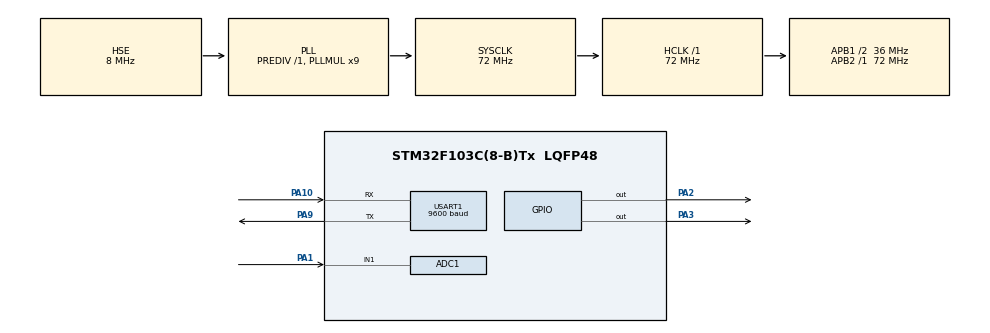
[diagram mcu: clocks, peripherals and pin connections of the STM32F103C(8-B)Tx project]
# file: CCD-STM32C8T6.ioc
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ADC1.Channel-0\#ChannelRegularConversion=ADC_CHANNEL_1
ADC1.NbrOfConversionFlag=1
ADC1.Rank-0\#ChannelRegularConversion=1
ADC1.SamplingTime-0\#ChannelRegularConversion=ADC_SAMPLETIME_1CYCLE_5
ADC1.master=1
Mcu.Family=STM32F1
Mcu.Name=STM32F103C(8-B)Tx
Mcu.Package=LQFP48
NVIC.PriorityGroup=NVIC_PRIORITYGROUP_4
NVIC.TIM2_IRQn=true\:0\:0\:false\:false\:true\:true\:true
NVIC.USART1_IRQn=true\:0\:0\:false\:false\:true\:true\:true
PA1.Signal=ADCx_IN1
PA10.Mode=Asynchronous
PA10.Signal=USART1_RX
PA13.Mode=Serial_Wire
PA13.Signal=SYS_JTMS-SWDIO
PA14.Mode=Serial_Wire
PA14.Signal=SYS_JTCK-SWCLK
PA2.Signal=GPIO_Output
PA3.Signal=GPIO_Output
PA9.Mode=Asynchronous
PA9.Signal=USART1_TX
PD0-OSC_IN.Mode=HSE-External-Oscillator
PD0-OSC_IN.Signal=RCC_OSC_IN
PD1-OSC_OUT.Mode=HSE-External-Oscillator
PD1-OSC_OUT.Signal=RCC_OSC_OUT
ProjectManager.HeapSize=0x200
ProjectManager.StackSize=0x400
ProjectManager.TargetToolchain=MDK-ARM V5.32
RCC.ADCPresc=RCC_ADCPCLK2_DIV6
RCC.AHBFreq_Value=72000000
RCC.APB1CLKDivider=RCC_HCLK_DIV2
RCC.APB1Freq_Value=36000000
RCC.APB1TimFreq_Value=72000000
RCC.APB2Freq_Value=72000000
RCC.APB2TimFreq_Value=72000000
RCC.HCLKFreq_Value=72000000
RCC.PLLMUL=RCC_PLL_MUL9
RCC.PLLSourceVirtual=RCC_PLLSOURCE_HSE
RCC.SYSCLKFreq_VALUE=72000000
RCC.SYSCLKSource=RCC_SYSCLKSOURCE_PLLCLK
RCC.USBFreq_Value=72000000
SH.ADCx_IN1.0=ADC1_IN1,IN1
TIM2.AutoReloadPreload=TIM_AUTORELOAD_PRELOAD_ENABLE
TIM2.Period=129
TIM2.Prescaler=71
USART1.BaudRate=9600
USART1.VirtualMode=VM_ASYNC
VP_TIM2_VS_ClockSourceINT.Mode=Internal
board=custom

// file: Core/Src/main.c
/* USER CODE BEGIN Header */
/**
  ******************************************************************************
  * @file           : main.c
  * @brief          : Main program body
  ******************************************************************************
  * @attention
  *
  * <h2><center>&copy; Copyright (c) 2023 STMicroelectronics.
  * All rights reserved.</center></h2>
  *
  * This software component is licensed by ST under BSD 3-Clause license,
  * the "License"; You may not use this file except in compliance with the
  * License. You may obtain a copy of the License at:
  *                        opensource.org/licenses/BSD-3-Clause
  *
  ******************************************************************************
  */
/* USER CODE END Header */
#include "main.h"
#include "adc.h"
#include "tim.h"
#include "usart.h"
#include "gpio.h"

/* USER CODE BEGIN Includes */
#include "sys.h"
/* USER CODE END Includes */

/* USER CODE BEGIN PM */
extern int pixel_array[]; //使用CCD.c定义的pixel_array[]
/* USER CODE END PM */

void SystemClock_Config(void);

int main(void)
{

  /* MCU Configuration--------------------------------------------------------*/

  /* Reset of all peripherals, Initializes the Flash interface and the Systick. */
  HAL_Init();

  /* Configure the system clock */
  SystemClock_Config();

  /* USER CODE BEGIN SysInit */
  delay_init();
  /* USER CODE END SysInit */

  /* Initialize all configured peripherals */
  MX_GPIO_Init();
  MX_ADC1_Init();
  MX_USART1_UART_Init();
  MX_TIM2_Init();

  /* Infinite loop */
  while (1)
  {
	delay_ms(100); //每秒串口发送一次pixel_array[]数据

		//for循环逐个发送次pixel_array数组中的128个灰度值数据
    for(int a=0;a<128;a++)
   {
		if(a==0)printf("[");
		printf("%d",  pixel_array[a]);
		if(a==127)printf(" ]\r\n");
		else printf(", ");
	 }
  }
}

void SystemClock_Config(void)
{
  RCC_OscInitTypeDef RCC_OscInitStruct = {0};
  RCC_ClkInitTypeDef RCC_ClkInitStruct = {0};
  RCC_PeriphCLKInitTypeDef PeriphClkInit = {0};

  /** Initializes the RCC Oscillators according to the specified parameters
  * in the RCC_OscInitTypeDef structure.
  */
  RCC_OscInitStruct.OscillatorType = RCC_OSCILLATORTYPE_HSE;
  RCC_OscInitStruct.HSEState = RCC_HSE_ON;
  RCC_OscInitStruct.HSEPredivValue = RCC_HSE_PREDIV_DIV1;
  RCC_OscInitStruct.HSIState = RCC_HSI_ON;
  RCC_OscInitStruct.PLL.PLLState = RCC_PLL_ON;
  RCC_OscInitStruct.PLL.PLLSource = RCC_PLLSOURCE_HSE;
  RCC_OscInitStruct.PLL.PLLMUL = RCC_PLL_MUL9;
  if (HAL_RCC_OscConfig(&RCC_OscInitStruct) != HAL_OK)
  {
    Error_Handler();
  }
  /** Initializes the CPU, AHB and APB buses clocks
  */
  RCC_ClkInitStruct.ClockType = RCC_CLOCKTYPE_HCLK|RCC_CLOCKTYPE_SYSCLK
                              |RCC_CLOCKTYPE_PCLK1|RCC_CLOCKTYPE_PCLK2;
  RCC_ClkInitStruct.SYSCLKSource = RCC_SYSCLKSOURCE_PLLCLK;
  RCC_ClkInitStruct.AHBCLKDivider = RCC_SYSCLK_DIV1;
  RCC_ClkInitStruct.APB1CLKDivider = RCC_HCLK_DIV2;
  RCC_ClkInitStruct.APB2CLKDivider = RCC_HCLK_DIV1;

  if (HAL_RCC_ClockConfig(&RCC_ClkInitStruct, FLASH_LATENCY_2) != HAL_OK)
  {
    Error_Handler();
  }
  PeriphClkInit.PeriphClockSelection = RCC_PERIPHCLK_ADC;
  PeriphClkInit.AdcClockSelection = RCC_ADCPCLK2_DIV6;
  if (HAL_RCCEx_PeriphCLKConfig(&PeriphClkInit) != HAL_OK)
  {
    Error_Handler();
  }
}

void Error_Handler(void)
{
  __disable_irq();
  while (1)
  {
  }
}

/************************ (C) COPYRIGHT STMicroelectronics *****END OF FILE****/
